# FT32F0xx register map
File version: 1.0
Registers are 32-bit, read-write, reset 0x0 unless marked. A register's access mark holds for its fields unless they carry their own. Offsets are from the block's base; lines under a group give offsets from that group; [hi:lo] are bit positions; {n}, {i} and the like mark numbered series; 'fields as' and 'values as' point back to an identical list; <NAME> marks a mode.

## Memory map
0x40000400 TIM3 size 0x400 — General-purpose-timers
0x40001000 TIM6 size 0x400 — Basic-timers
0x40002000 TIM14 size 0x400 — General-purpose-timers
0x40002800 RTC size 0x400 — Real-time clock
0x40002C00 WWDG size 0x400 — Window watchdog
0x40003000 IWDG size 0x400 — Independent watchdog
0x40003800 SPI2 size 0x400
0x40004400 USART2 size 0x400
0x40005400 I2C1 size 0x400 — Inter-integrated circuit
0x40005800 I2C2 size 0x400
0x40005C00 USB size 0x400 — Universal serial bus full-speed device interface
0x40007000 PWR size 0x400 — Power control
0x4000FC00 LEB size 0x400 — LEB and FLT support
0x40010000 SYSCFG size 0x1C — System configuration controller
0x4001001C COMP size 0x14 — Comparator
0x40010030 OP size 0x14 — operational support
0x40010080 DIV size 0x14 — DIV support
0x40010400 EXTI size 0x400 — External interrupt/event controller
0x40012400 ADC size 0x400 — Analog-to-digital converter
0x40012C00 TIM1 size 0x400 — Advanced-timers
0x40013000 SPI1 size 0x400 — Serial peripheral interface
0x40013800 USART1 size 0x400 — Universal synchronous asynchronous receiver transmitter
0x40014000 TIM15 size 0x400 — General-purpose-timers
0x40014400 TIM16 size 0x400 — General-purpose-timers
0x40014800 TIM17 size 0x400
0x40015800 DEBUG size 0x400 — Debug support
0x40020000 DMA size 0x400 — DMA controller
0x40021000 RCC size 0x400 — Reset and clock control
0x40022000 Flash size 0x400
0x40023000 CRC size 0x400 — cyclic redundancy check calculation unit
0x40024000 TSC size 0x400 — Touch sensing controller
0x48000000 GPIOA size 0x400 — General-purpose I/Os
0x48000400 GPIOB size 0x400
0x48000800 GPIOC size 0x400
0x48000C00 GPIOD size 0x400
0x48001400 GPIOF size 0x400 — General-purpose I/Os
0xE000E100 NVIC size 0x33D — Nested Vectored Interrupt Controller

## Interrupts
0 WWDG — Window Watchdog interrupt
1 PVD (EXTI) — PVD and VDDIO2 supply comparator interrupt
2 RTC — RTC interrupts
3 FLASH (Flash) — Flash global interrupt
4 RCC_CRS (RCC) — RCC and CRS global interrupts
5 EXTI0_1 (EXTI) — EXTI Line[1:0] interrupts
6 EXTI2_3 (EXTI) — EXTI Line[3:2] interrupts
7 EXTI4_15 (EXTI) — EXTI Line15 and EXTI4 interrupts
8 TSC — Touch sensing interrupt
9 DMA_CH1 (DMA) — DMA channel 1 interrupt
10 DMA_CH2_3 (DMA) — DMA channel 2 and 3 interrupts
11 DMA_CH4_5_6_7 (DMA) — DMA channel 4, 5, 6 and 7 interrupts
12 ADC_COMP (ADC, COMP) — ADC and comparator interrupts
13 TIM1_BRK_UP_TRG_COM (TIM1) — TIM1 break, update, trigger and commutation interrupt
14 TIM1_CC (TIM1) — TIM1 Capture Compare interrupt
16 TIM3 — TIM3 global interrupt
17 TIM6_DAC (TIM6) — TIM6 global interrupt and DAC underrun interrupt
19 TIM14 — TIM14 global interrupt
20 TIM15 — TIM15 global interrupt
21 TIM16 — TIM16 global interrupt
22 TIM17 — TIM17 global interrupt
23 I2C1 — I2C1 global interrupt
24 I2C2 — I2C2 global interrupt
25 SPI1 — SPI1_global_interrupt
26 SPI2 — SPI2 global interrupt
27 USART1 — USART1 global interrupt
28 USART2 — USART2 global interrupt
31 USB — USB global interrupt

## CRC — cyclic redundancy check calculation unit
Base 0x40023000
0x00 DR reset 0xFFFFFFFF — Data register
  [31:0] DR — Data register bits
0x04 IDR — Independent data register
  [7:0] IDR — General-purpose 8-bit data register bits
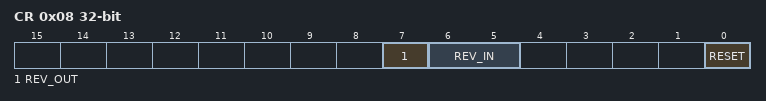
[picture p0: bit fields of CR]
0x08 CR — Control register
  [7] REV_OUT — Reverse output data
  [6:5] REV_IN — Reverse input data
  [0] RESET — reset bit
0x0C INIT reset 0xFFFFFFFF — Initial CRC value
  [31:0] INIT — Programmable initial CRC value

## GPIOF — General-purpose I/Os
Base 0x48001400
Same registers: GPIOB 0x48000400, GPIOC 0x48000800, GPIOD 0x48000C00
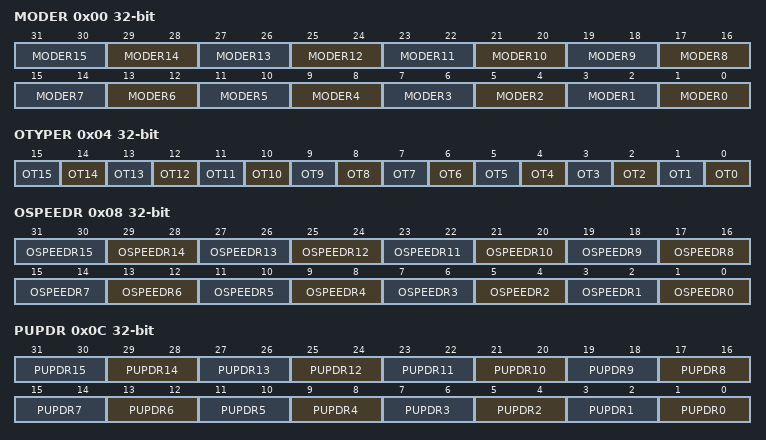
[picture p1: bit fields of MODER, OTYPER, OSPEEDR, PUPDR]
0x00 MODER — GPIO port mode register
  [2n+1:2n] MODER{n} (n=0..15) — Port x configuration bits (y = 0..15)
0x04 OTYPER — GPIO port output type register
  [n] OT{n} (n=0..15) — Port x configuration bit {n}
0x08 OSPEEDR — GPIO port output speed register
  [2n+1:2n] OSPEEDR{n} (n=0..15) — Port x configuration bits (y = 0..15)
0x0C PUPDR — GPIO port pull-up/pull-down register
  [2n+1:2n] PUPDR{n} (n=0..15) — Port x configuration bits (y = 0..15)
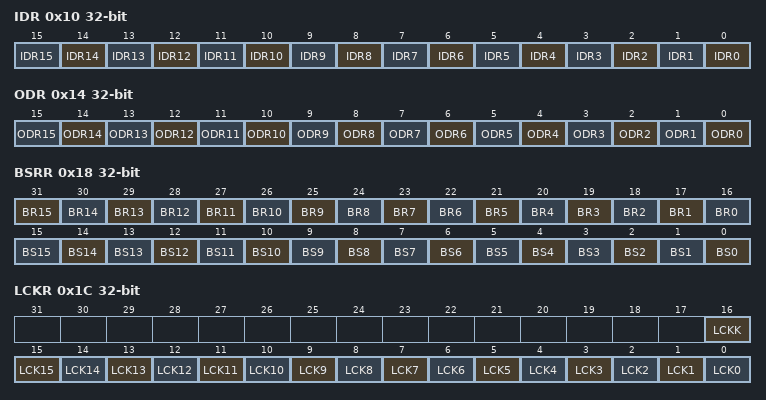
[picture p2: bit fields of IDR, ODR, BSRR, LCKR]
0x10 IDR ro — GPIO port input data register
  [n] IDR{n} (n=0..15) — Port input data (y = 0..15)
0x14 ODR — GPIO port output data register
  [n] ODR{n} (n=0..15) — Port output data (y = 0..15)
0x18 BSRR wo — GPIO port bit set/reset register
  [n+16] BR{n} (n=1..15) — Port x reset bit y (y = 0..15)
  [16] BR0 — Port x set bit y (y= 0..15)
  [n] BS{n} (n=0..15) — Port x set bit y (y= 0..15)
0x1C LCKR — GPIO port configuration lock register
  [16] LCKK — Port x lock bit y
  [n] LCK{n} (n=0..15) — Port x lock bit y (y= 0..15)
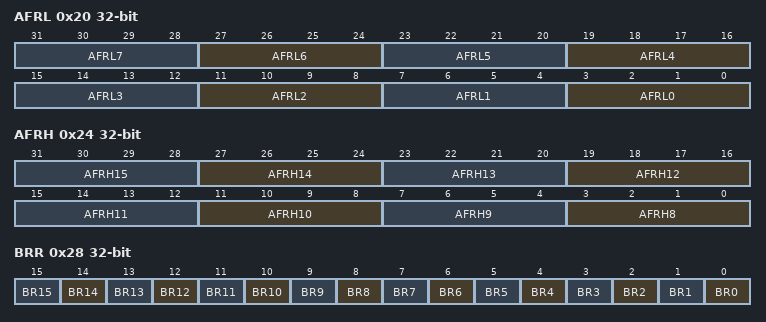
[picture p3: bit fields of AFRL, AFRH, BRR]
0x20 AFRL — GPIO alternate function low register
  [4n+3:4n] AFRL{n} (n=0..7) — Alternate function selection for port x bit y (y = 0..7)
0x24 AFRH — GPIO alternate function high register
  [4n-29:4n-32] AFRH{n} (n=8..15) — Alternate function selection for port x bit y (y = 8..15)
0x28 BRR wo — Port bit reset register
  [n] BR{n} (n=0..15) — Port x Reset bit y

## GPIOA — General-purpose I/Os
Base 0x48000000
Registers as GPIOF; these are added or differ:
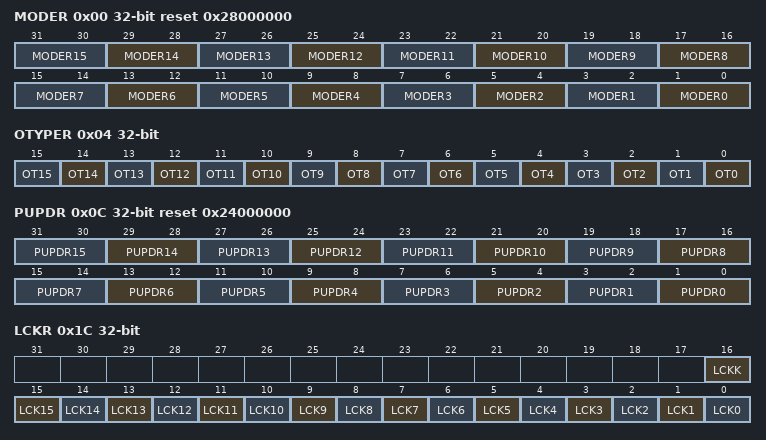
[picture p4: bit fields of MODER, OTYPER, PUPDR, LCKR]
0x00 MODER reset 0x28000000 — GPIO port mode register
  [2n+1:2n] MODER{n} (n=0..15) — Port x configuration bits (y = 0..15)
0x04 OTYPER — GPIO port output type register
  [n] OT{n} (n=0..15) — Port x configuration bits (y = 0..15)
0x0C PUPDR reset 0x24000000 — GPIO port pull-up/pull-down register
  [2n+1:2n] PUPDR{n} (n=0..15) — Port x configuration bits (y = 0..15)
0x1C LCKR — GPIO port configuration lock register
  [16] LCKK — Port x lock bit y (y= 0..15)
  [n] LCK{n} (n=0..15) — Port x lock bit y (y= 0..15)
